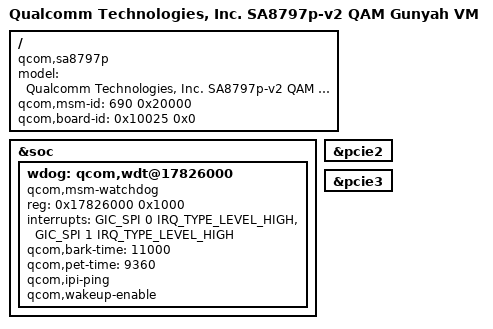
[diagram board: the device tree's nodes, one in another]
// SPDX-License-Identifier: BSD-3-Clause
/*
 * Copyright (c) Qualcomm Technologies, Inc. and/or its subsidiaries.
 */

/dts-v1/;

#include "sa8797p-gunyah-vm-qam.dtsi"

/ {
	model = "Qualcomm Technologies, Inc. SA8797p-v2 QAM Gunyah VM";
	compatible = "qcom,sa8797p", "qcom,qam";
	qcom,msm-id = <690 0x20000>;
	qcom,board-id = <0x10025 0x0>;
};

&soc {
	wdog: qcom,wdt@17826000 {
		compatible = "qcom,msm-watchdog";
		reg = <0x17826000 0x1000>;
		reg-names = "wdt-base";
		interrupts = <GIC_SPI 0 IRQ_TYPE_LEVEL_HIGH>,
			<GIC_SPI 1 IRQ_TYPE_LEVEL_HIGH>;
		qcom,bark-time = <11000>;
		qcom,pet-time = <9360>;
		qcom,ipi-ping;
		qcom,wakeup-enable;
	};
};

&pcie2 {
	ranges = <0x01000000 0x0 0x60000000 0x0 0x60000000 0x0 0x100000>,
		<0x02000000 0x0 0x60100000 0x0 0x60100000 0x0 0x7000000>,
		<0x43000000 0x40 0x10100000 0x40 0x10100000 0x0 0x100000>;
};

&pcie3 {
	ranges = <0x01000000 0x0 0x70000000 0x0 0x70000000 0x0 0x100000>,
		<0x02000000 0x0 0x70100000 0x0 0x70100000 0x0 0x7000000>,
		<0x43000000 0x4 0x10100000 0x4 0x10100000 0x0 0x100000>;
};
